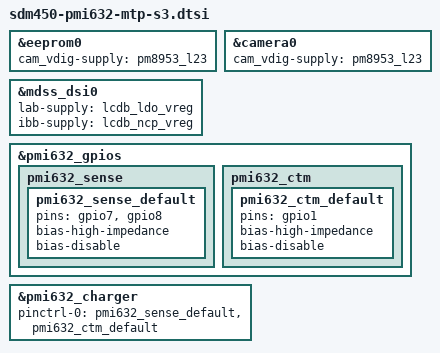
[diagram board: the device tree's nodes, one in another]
/*
 * Copyright (c) 2018-2019, The Linux Foundation. All rights reserved.
 *
 * This program is free software; you can redistribute it and/or modify
 * it under the terms of the GNU General Public License version 2 and
 * only version 2 as published by the Free Software Foundation.
 *
 * This program is distributed in the hope that it will be useful,
 * but WITHOUT ANY WARRANTY; without even the implied warranty of
 * MERCHANTABILITY or FITNESS FOR A PARTICULAR PURPOSE.  See the
 * GNU General Public License for more details.
 */

#include "msm8953-mtp.dtsi"

&eeprom0 {
	cam_vdig-supply = <&pm8953_l23>;
};

&camera0 {
	cam_vdig-supply = <&pm8953_l23>;
};

&mdss_dsi0 {
	pinctrl-names = "mdss_default", "mdss_sleep";
	lab-supply = <&lcdb_ldo_vreg>;
	ibb-supply = <&lcdb_ncp_vreg>;

};

&pmi632_gpios {
	pmi632_sense {
		/* GPIO 7 and 8 are external-sense pins for PMI632 */
		pmi632_sense_default: pmi632_sense_default {
			pins = "gpio7", "gpio8";
			bias-high-impedance;	/* disable the GPIO */
			bias-disable;		/* no-pull */
		};
	};

	pmi632_ctm {
		/* Disable GPIO1 for h/w base mitigation */
		pmi632_ctm_default: pmi632_ctm_default {
			pins = "gpio1";
			bias-high-impedance;	/* disable the GPIO */
			bias-disable;		/* no-pull */
		};
	};
};

&pmi632_charger {
	pinctrl-names = "default";
	pinctrl-0 = <&pmi632_sense_default &pmi632_ctm_default>;
};
